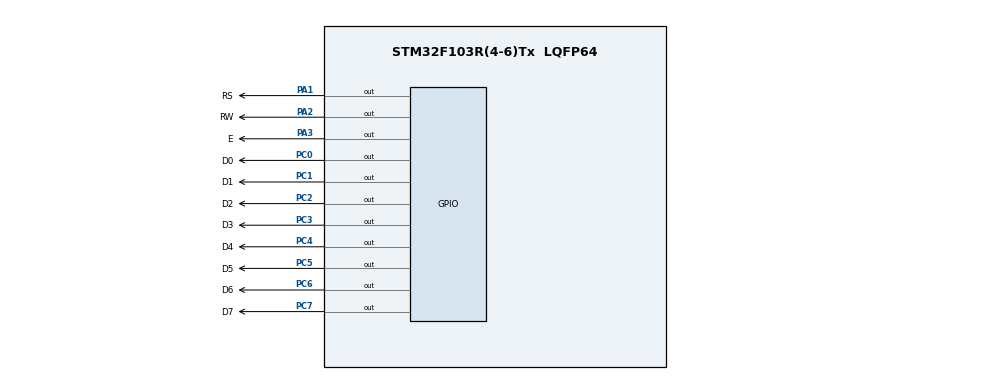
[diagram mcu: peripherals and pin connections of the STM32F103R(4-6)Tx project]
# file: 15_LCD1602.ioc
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Mcu.Family=STM32F1
Mcu.Name=STM32F103R(4-6)Tx
Mcu.Package=LQFP64
NVIC.PriorityGroup=NVIC_PRIORITYGROUP_4
PA1.GPIO_Label=RS
PA1.PinState=GPIO_PIN_SET
PA1.Signal=GPIO_Output
PA2.GPIO_Label=RW
PA2.PinState=GPIO_PIN_SET
PA2.Signal=GPIO_Output
PA3.GPIO_Label=E
PA3.PinState=GPIO_PIN_SET
PA3.Signal=GPIO_Output
PC0.GPIO_Label=D0
PC0.PinState=GPIO_PIN_SET
PC0.Signal=GPIO_Output
PC1.GPIO_Label=D1
PC1.PinState=GPIO_PIN_SET
PC1.Signal=GPIO_Output
PC2.GPIO_Label=D2
PC2.PinState=GPIO_PIN_SET
PC2.Signal=GPIO_Output
PC3.GPIO_Label=D3
PC3.PinState=GPIO_PIN_SET
PC3.Signal=GPIO_Output
PC4.GPIO_Label=D4
PC4.PinState=GPIO_PIN_SET
PC4.Signal=GPIO_Output
PC5.GPIO_Label=D5
PC5.PinState=GPIO_PIN_SET
PC5.Signal=GPIO_Output
PC6.GPIO_Label=D6
PC6.PinState=GPIO_PIN_SET
PC6.Signal=GPIO_Output
PC7.GPIO_Label=D7
PC7.PinState=GPIO_PIN_SET
PC7.Signal=GPIO_Output
ProjectManager.HeapSize=0x200
ProjectManager.StackSize=0x400
ProjectManager.TargetToolchain=MDK-ARM V5.32
RCC.APB1Freq_Value=8000000
RCC.APB2Freq_Value=8000000
VP_SYS_VS_ND.Mode=No_Debug
board=custom

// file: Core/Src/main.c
/* USER CODE BEGIN Header */
/**
  ******************************************************************************
  * @file           : main.c
  * @brief          : Main program body
  ******************************************************************************
  * @attention
  *
  * Copyright (c) 2022 STMicroelectronics.
  * All rights reserved.
  *
  * This software is licensed under terms that can be found in the LICENSE file
  * in the root directory of this software component.
  * If no LICENSE file comes with this software, it is provided AS-IS.
  *
  ******************************************************************************
  */
/* USER CODE END Header */
#include "main.h"
#include "gpio.h"

/* USER CODE BEGIN Includes */
#include "LCD1602.h"    //用户自定义头文件
/* USER CODE END Includes */

void SystemClock_Config(void);

int main(void)
{
  /* USER CODE BEGIN 1 */
	char str[]="Hello World!";  //输出字符串内容设置
  /* USER CODE END 1 */

  /* MCU Configuration--------------------------------------------------------*/

  /* Reset of all peripherals, Initializes the Flash interface and the Systick. */
  HAL_Init();

  /* Configure the system clock */
  SystemClock_Config();

  /* Initialize all configured peripherals */
  MX_GPIO_Init();
  /* USER CODE BEGIN 2 */
	LCD_Init();  //初始化LCD1602
	LCD_ShowString(0,0,str);  //LCD 显示设定字符串
  /* USER CODE END 2 */

  /* Infinite loop */
  while (1)
  {

  }
}

void SystemClock_Config(void)
{
  RCC_OscInitTypeDef RCC_OscInitStruct = {0};
  RCC_ClkInitTypeDef RCC_ClkInitStruct = {0};

  /** Initializes the RCC Oscillators according to the specified parameters
  * in the RCC_OscInitTypeDef structure.
  */
  RCC_OscInitStruct.OscillatorType = RCC_OSCILLATORTYPE_HSI;
  RCC_OscInitStruct.HSIState = RCC_HSI_ON;
  RCC_OscInitStruct.HSICalibrationValue = RCC_HSICALIBRATION_DEFAULT;
  RCC_OscInitStruct.PLL.PLLState = RCC_PLL_NONE;
  if (HAL_RCC_OscConfig(&RCC_OscInitStruct) != HAL_OK)
  {
    Error_Handler();
  }

  /** Initializes the CPU, AHB and APB buses clocks
  */
  RCC_ClkInitStruct.ClockType = RCC_CLOCKTYPE_HCLK|RCC_CLOCKTYPE_SYSCLK
                              |RCC_CLOCKTYPE_PCLK1|RCC_CLOCKTYPE_PCLK2;
  RCC_ClkInitStruct.SYSCLKSource = RCC_SYSCLKSOURCE_HSI;
  RCC_ClkInitStruct.AHBCLKDivider = RCC_SYSCLK_DIV1;
  RCC_ClkInitStruct.APB1CLKDivider = RCC_HCLK_DIV1;
  RCC_ClkInitStruct.APB2CLKDivider = RCC_HCLK_DIV1;

  if (HAL_RCC_ClockConfig(&RCC_ClkInitStruct, FLASH_LATENCY_0) != HAL_OK)
  {
    Error_Handler();
  }
}

void Error_Handler(void)
{
  __disable_irq();
  while (1)
  {
  }
}
